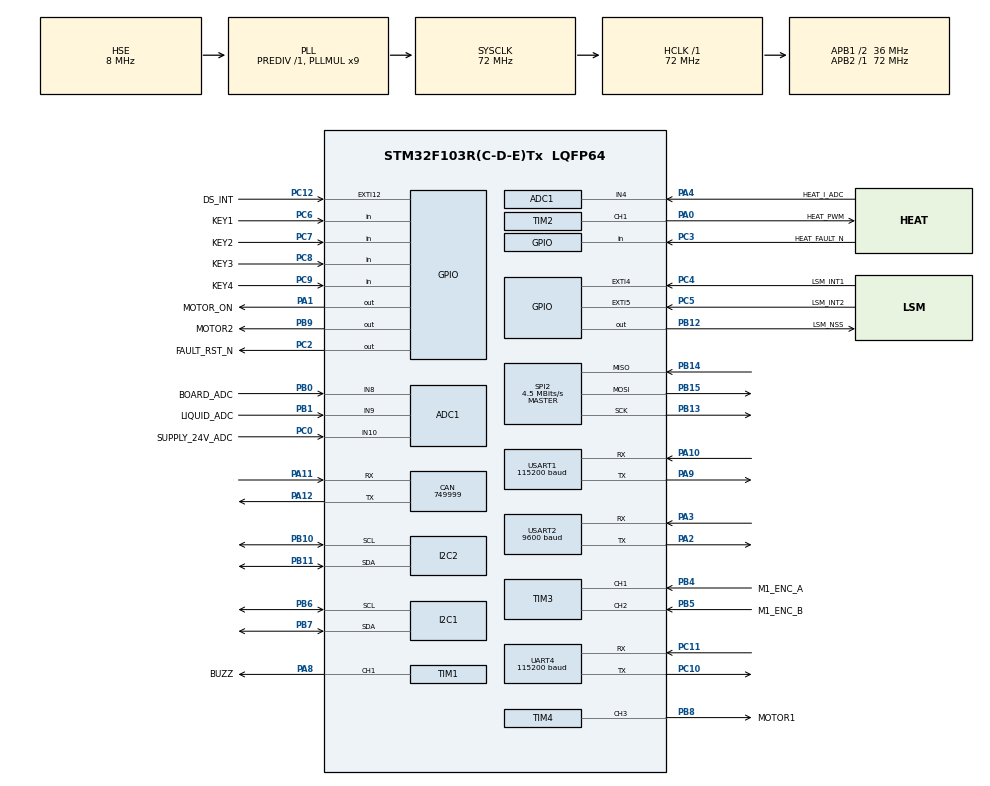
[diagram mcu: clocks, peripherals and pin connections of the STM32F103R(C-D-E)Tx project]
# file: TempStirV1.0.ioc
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ADC1.Channel-0\#ChannelRegularConversion=ADC_CHANNEL_4
ADC1.Channel-1\#ChannelRegularConversion=ADC_CHANNEL_8
ADC1.Channel-2\#ChannelRegularConversion=ADC_CHANNEL_9
ADC1.Channel-3\#ChannelRegularConversion=ADC_CHANNEL_10
ADC1.ContinuousConvMode=ENABLE
ADC1.NbrOfConversionFlag=4
ADC1.Rank-0\#ChannelRegularConversion=1
ADC1.Rank-1\#ChannelRegularConversion=2
ADC1.Rank-2\#ChannelRegularConversion=3
ADC1.Rank-3\#ChannelRegularConversion=4
ADC1.SamplingTime-0\#ChannelRegularConversion=ADC_SAMPLETIME_239CYCLES_5
ADC1.SamplingTime-1\#ChannelRegularConversion=ADC_SAMPLETIME_239CYCLES_5
ADC1.SamplingTime-2\#ChannelRegularConversion=ADC_SAMPLETIME_239CYCLES_5
ADC1.SamplingTime-3\#ChannelRegularConversion=ADC_SAMPLETIME_239CYCLES_5
ADC1.ScanConvMode=ADC_SCAN_DISABLE
ADC1.master=1
CAN.CalculateBaudRate=749999
CAN.CalculateTimeBit=1333
CAN.CalculateTimeQuantum=444.44444444444446
Mcu.Family=STM32F1
Mcu.Name=STM32F103R(C-D-E)Tx
Mcu.Package=LQFP64
NVIC.EXTI15_10_IRQn=true\:6\:0\:true\:false\:true\:true\:true\:true
NVIC.EXTI4_IRQn=true\:6\:0\:true\:false\:true\:true\:true\:true
NVIC.EXTI9_5_IRQn=true\:6\:0\:true\:false\:true\:true\:true\:true
NVIC.PriorityGroup=NVIC_PRIORITYGROUP_4
NVIC.TIM6_IRQn=true\:4\:0\:false\:false\:true\:false\:true\:true
NVIC.TimeBase=TIM6_IRQn
NVIC.TimeBaseIP=TIM6
NVIC.UART4_IRQn=true\:5\:0\:true\:false\:true\:true\:true\:true
NVIC.USART2_IRQn=true\:5\:0\:true\:false\:true\:true\:true\:true
NVIC.USB_LP_CAN1_RX0_IRQn=true\:0\:0\:false\:false\:true\:true\:true\:true
PA0-WKUP.GPIO_Label=HEAT_PWM
PA0-WKUP.Signal=S_TIM2_CH1_ETR
PA1.GPIO_Label=MOTOR_ON
PA1.GPIO_ModeDefaultOutput=GPIO_MODE_OUTPUT_PP
PA1.PinState=GPIO_PIN_RESET
PA1.Signal=GPIO_Output
PA10.GPIO_PuPd=GPIO_PULLUP
PA10.Mode=Asynchronous
PA10.Signal=USART1_RX
PA11.Mode=CAN_Activate
PA11.Signal=CAN_RX
PA12.Mode=CAN_Activate
PA12.Signal=CAN_TX
PA13.Mode=Serial_Wire
PA13.Signal=SYS_JTMS-SWDIO
PA14.Mode=Serial_Wire
PA14.Signal=SYS_JTCK-SWCLK
PA2.Mode=Asynchronous
PA2.Signal=USART2_TX
PA3.GPIO_PuPd=GPIO_PULLUP
PA3.Mode=Asynchronous
PA3.Signal=USART2_RX
PA4.GPIO_Label=HEAT_I_ADC
PA4.Signal=ADCx_IN4
PA8.GPIO_Label=BUZZ
PA8.Signal=S_TIM1_CH1
PA9.Mode=Asynchronous
PA9.Signal=USART1_TX
PB0.GPIO_Label=BOARD_ADC
PB0.Signal=ADCx_IN8
PB1.GPIO_Label=LIQUID_ADC
PB1.Signal=ADCx_IN9
PB10.Mode=I2C
PB10.Signal=I2C2_SCL
PB11.Mode=I2C
PB11.Signal=I2C2_SDA
PB12.GPIO_Label=LSM_NSS
PB12.GPIO_ModeDefaultOutput=GPIO_MODE_OUTPUT_PP
PB12.PinState=GPIO_PIN_SET
PB12.Signal=GPIO_Output
PB13.Mode=Full_Duplex_Master
PB13.Signal=SPI2_SCK
PB14.Mode=Full_Duplex_Master
PB14.Signal=SPI2_MISO
PB15.Mode=Full_Duplex_Master
PB15.Signal=SPI2_MOSI
PB4.GPIO_Label=M1_ENC_A
PB4.GPIO_PuPd=GPIO_PULLUP
PB4.Signal=S_TIM3_CH1
PB5.GPIO_Label=M1_ENC_B
PB5.GPIO_PuPd=GPIO_PULLUP
PB5.Signal=S_TIM3_CH2
PB6.Mode=I2C
PB6.Signal=I2C1_SCL
PB7.Mode=I2C
PB7.Signal=I2C1_SDA
PB8.GPIO_Label=MOTOR1
PB8.Signal=S_TIM4_CH3
PB9.GPIO_Label=MOTOR2
PB9.GPIO_ModeDefaultOutput=GPIO_MODE_OUTPUT_PP
PB9.PinState=GPIO_PIN_RESET
PB9.Signal=GPIO_Output
PC0.GPIO_Label=SUPPLY_24V_ADC
PC0.Signal=ADCx_IN10
PC10.Mode=Asynchronous
PC10.Signal=UART4_TX
PC11.GPIO_PuPd=GPIO_PULLUP
PC11.Mode=Asynchronous
PC11.Signal=UART4_RX
PC12.GPIO_Label=DS_INT
PC12.GPIO_ModeDefaultEXTI=GPIO_MODE_IT_FALLING
PC12.GPIO_PuPd=GPIO_NOPULL
PC12.Signal=GPXTI12
PC2.GPIO_Label=FAULT_RST_N
PC2.GPIO_ModeDefaultOutput=GPIO_MODE_OUTPUT_OD
PC2.PinState=GPIO_PIN_SET
PC2.Signal=GPIO_Output
PC3.GPIO_Label=HEAT_FAULT_N
PC3.GPIO_PuPd=GPIO_NOPULL
PC3.Signal=GPIO_Input
PC4.GPIO_Label=LSM_INT1
PC4.GPIO_ModeDefaultEXTI=GPIO_MODE_IT_RISING
PC4.Signal=GPXTI4
PC5.GPIO_Label=LSM_INT2
PC5.GPIO_ModeDefaultEXTI=GPIO_MODE_IT_RISING
PC5.Signal=GPXTI5
PC6.GPIO_Label=KEY1
PC6.GPIO_PuPd=GPIO_PULLUP
PC6.Signal=GPIO_Input
PC7.GPIO_Label=KEY2
PC7.GPIO_PuPd=GPIO_PULLUP
PC7.Signal=GPIO_Input
PC8.GPIO_Label=KEY3
PC8.GPIO_PuPd=GPIO_PULLUP
PC8.Signal=GPIO_Input
PC9.GPIO_Label=KEY4
PC9.GPIO_PuPd=GPIO_PULLUP
PC9.Signal=GPIO_Input
PD0-OSC_IN.Mode=HSE-External-Oscillator
PD0-OSC_IN.Signal=RCC_OSC_IN
PD1-OSC_OUT.Mode=HSE-External-Oscillator
PD1-OSC_OUT.Signal=RCC_OSC_OUT
ProjectManager.HeapSize=0x200
ProjectManager.StackSize=0x400
ProjectManager.TargetToolchain=MDK-ARM V5.32
RCC.ADCPresc=RCC_ADCPCLK2_DIV6
RCC.AHBFreq_Value=72000000
RCC.APB1CLKDivider=RCC_HCLK_DIV2
RCC.APB1Freq_Value=36000000
RCC.APB1TimFreq_Value=72000000
RCC.APB2Freq_Value=72000000
RCC.APB2TimFreq_Value=72000000
RCC.HCLKFreq_Value=72000000
RCC.PLLMUL=RCC_PLL_MUL9
RCC.PLLSourceVirtual=RCC_PLLSOURCE_HSE
RCC.SYSCLKFreq_VALUE=72000000
RCC.SYSCLKSource=RCC_SYSCLKSOURCE_PLLCLK
RCC.USBFreq_Value=72000000
SH.ADCx_IN10.0=ADC1_IN10,IN10
SH.ADCx_IN4.0=ADC1_IN4,IN4
SH.ADCx_IN8.0=ADC1_IN8,IN8
SH.ADCx_IN9.0=ADC1_IN9,IN9
SH.S_TIM1_CH1.0=TIM1_CH1,PWM Generation1 CH1
SH.S_TIM2_CH1_ETR.0=TIM2_CH1,PWM Generation1 CH1
SH.S_TIM3_CH1.0=TIM3_CH1,Encoder_Interface
SH.S_TIM3_CH2.0=TIM3_CH2,Encoder_Interface
SH.S_TIM4_CH3.0=TIM4_CH3,PWM Generation3 CH3
SPI2.BaudRatePrescaler=SPI_BAUDRATEPRESCALER_8
SPI2.CalculateBaudRate=4.5 MBits/s
SPI2.Direction=SPI_DIRECTION_2LINES
SPI2.Mode=SPI_MODE_MASTER
SPI2.VirtualType=VM_MASTER
SYS.Debug=Serial Wire
TIM1.Channel-PWM\ Generation1\ CH1=TIM_CHANNEL_1
TIM1.Period=17999
TIM2.Channel-PWM\ Generation1\ CH1=TIM_CHANNEL_1
TIM2.Period=3599
TIM2.Prescaler=0
TIM3.EncoderMode=TIM_ENCODERMODE_TI12
TIM3.IC1Filter=6
TIM3.IC2Filter=6
TIM4.Channel-PWM\ Generation3\ CH3=TIM_CHANNEL_3
TIM4.Period=3599
UART4.BaudRate=115200
UART4.VirtualMode=Asynchronous
USART1.BaudRate=115200
USART1.VirtualMode=VM_ASYNC
USART2.BaudRate=9600
USART2.VirtualMode=VM_ASYNC
VP_SYS_VS_tim6.Mode=TIM6
VP_TIM1_VS_ClockSourceINT.Mode=Internal
VP_TIM2_VS_ClockSourceINT.Mode=Internal
VP_TIM4_VS_ClockSourceINT.Mode=Internal
board=custom

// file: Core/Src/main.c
/* USER CODE BEGIN Header */
/**
  ******************************************************************************
  * @file           : main.c
  * @brief          : Main program body
  ******************************************************************************
  * @attention
  *
  * Copyright (c) 2026 STMicroelectronics.
  * All rights reserved.
  *
  * This software is licensed under terms that can be found in the LICENSE file
  * in the root directory of this software component.
  * If no LICENSE file comes with this software, it is provided AS-IS.
  *
  ******************************************************************************
  */
/* USER CODE END Header */
#include "main.h"
#include "adc.h"
#include "can.h"
#include "i2c.h"
#include "spi.h"
#include "tim.h"
#include "usart.h"
#include "gpio.h"

/* USER CODE BEGIN Includes */
/* FreeRTOS 内核头文件。注意：FreeRTOSConfig.h 位于 MDK-ARM/freertos，
   已加入 Keil 头文件搜索路径。此处的验证任务仅用于确认移植可用，
   后续业务任务请放到 MDK-ARM/User/App 中。 */
#include "FreeRTOS.h"
#include "task.h"
#include "app_main.h"   /* 业务应用层（MDK-ARM/User/App）FreeRTOS 封装 */
#include <stdio.h>          /* printf 已重定向到 USART1（见 usart.c） */
/* USER CODE END Includes */

void SystemClock_Config(void);
/* USER CODE BEGIN PFP */
/* 业务应用层入口在 MDK-ARM/User/App/app_main.c 中实现（App_Main_Init）。 */
/* USER CODE END PFP */

int main(void)
{

  /* MCU Configuration--------------------------------------------------------*/

  /* Reset of all peripherals, Initializes the Flash interface and the Systick. */
  HAL_Init();

  /* Configure the system clock */
  SystemClock_Config();

  /* Initialize all configured peripherals */
  MX_GPIO_Init();
  MX_ADC1_Init();
  MX_I2C1_Init();
  MX_I2C2_Init();
  MX_SPI2_Init();
  MX_TIM1_Init();
  MX_TIM2_Init();
  MX_TIM3_Init();
  MX_TIM4_Init();
  MX_UART4_Init();
  MX_USART1_UART_Init();
  MX_USART2_UART_Init();
  MX_CAN_Init();
  /* USER CODE BEGIN 2 */
  /* 程序入口： */
  App_Main_Init();

  /* USER CODE END 2 */

  /* Infinite loop */
  while (1)
  {

  }
}

void SystemClock_Config(void)
{
  RCC_OscInitTypeDef RCC_OscInitStruct = {0};
  RCC_ClkInitTypeDef RCC_ClkInitStruct = {0};
  RCC_PeriphCLKInitTypeDef PeriphClkInit = {0};

  /** Initializes the RCC Oscillators according to the specified parameters
  * in the RCC_OscInitTypeDef structure.
  */
  RCC_OscInitStruct.OscillatorType = RCC_OSCILLATORTYPE_HSE;
  RCC_OscInitStruct.HSEState = RCC_HSE_ON;
  RCC_OscInitStruct.HSEPredivValue = RCC_HSE_PREDIV_DIV1;
  RCC_OscInitStruct.HSIState = RCC_HSI_ON;
  RCC_OscInitStruct.PLL.PLLState = RCC_PLL_ON;
  RCC_OscInitStruct.PLL.PLLSource = RCC_PLLSOURCE_HSE;
  RCC_OscInitStruct.PLL.PLLMUL = RCC_PLL_MUL9;
  if (HAL_RCC_OscConfig(&RCC_OscInitStruct) != HAL_OK)
  {
    Error_Handler();
  }

  /** Initializes the CPU, AHB and APB buses clocks
  */
  RCC_ClkInitStruct.ClockType = RCC_CLOCKTYPE_HCLK|RCC_CLOCKTYPE_SYSCLK
                              |RCC_CLOCKTYPE_PCLK1|RCC_CLOCKTYPE_PCLK2;
  RCC_ClkInitStruct.SYSCLKSource = RCC_SYSCLKSOURCE_PLLCLK;
  RCC_ClkInitStruct.AHBCLKDivider = RCC_SYSCLK_DIV1;
  RCC_ClkInitStruct.APB1CLKDivider = RCC_HCLK_DIV2;
  RCC_ClkInitStruct.APB2CLKDivider = RCC_HCLK_DIV1;

  if (HAL_RCC_ClockConfig(&RCC_ClkInitStruct, FLASH_LATENCY_2) != HAL_OK)
  {
    Error_Handler();
  }
  PeriphClkInit.PeriphClockSelection = RCC_PERIPHCLK_ADC;
  PeriphClkInit.AdcClockSelection = RCC_ADCPCLK2_DIV6;
  if (HAL_RCCEx_PeriphCLKConfig(&PeriphClkInit) != HAL_OK)
  {
    Error_Handler();
  }
}

/* USER CODE BEGIN 4 */

/* 验证任务与 printf 串口测试任务已迁移至 MDK-ARM/User/App/app_main.c
   （App_Main_Init → App_Main_PrintfTask），本区域保留供后续扩展。 */

/* USER CODE END 4 */

void HAL_TIM_PeriodElapsedCallback(TIM_HandleTypeDef *htim)
{
  if (htim->Instance == TIM6)
  {
    HAL_IncTick();
  }
}

void Error_Handler(void)
{
  __disable_irq();
  while (1)
  {
  }
}
